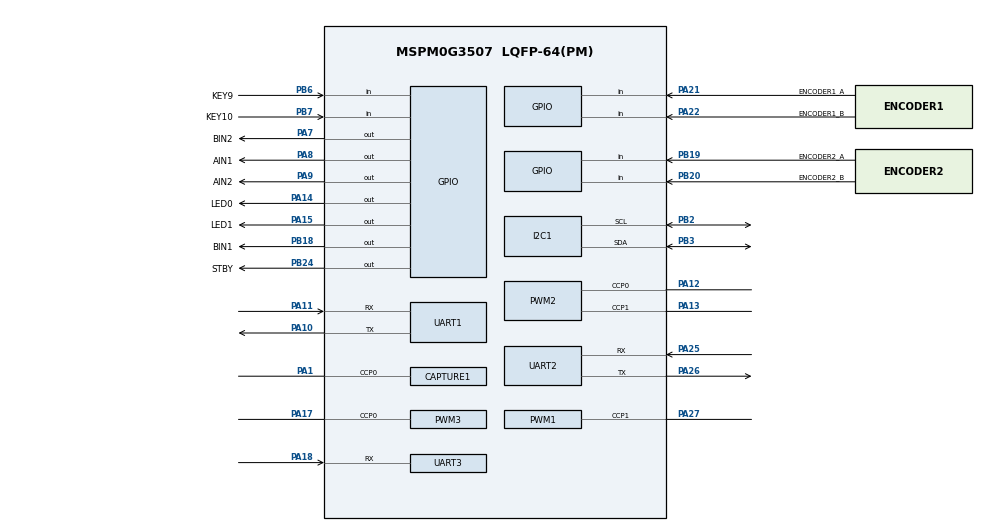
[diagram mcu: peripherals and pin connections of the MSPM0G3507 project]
/**
 * These arguments were used when this file was generated. They will be automatically applied on subsequent loads
 * via the GUI or CLI. Run CLI with '--help' for additional information on how to override these arguments.
 * @cliArgs --device "MSPM0G350X" --part "Default" --package "LQFP-64(PM)" --product "mspm0_sdk@2.10.00.04"
 * @v2CliArgs --device "MSPM0G3507" --package "LQFP-64(PM)" --product "mspm0_sdk@2.10.00.04"
 * @versions {"tool":"1.26.2+4477"}
 */

/**
 * Import the modules used in this configuration.
 */
const ADC12    = scripting.addModule("/ti/driverlib/ADC12", {}, false);
const ADC121   = ADC12.addInstance();
const CAPTURE  = scripting.addModule("/ti/driverlib/CAPTURE", {}, false);
const CAPTURE1 = CAPTURE.addInstance();
const GPIO     = scripting.addModule("/ti/driverlib/GPIO", {}, false);
const GPIO1    = GPIO.addInstance();
const GPIO2    = GPIO.addInstance();
const GPIO3    = GPIO.addInstance();
const I2C      = scripting.addModule("/ti/driverlib/I2C", {}, false);
const I2C1     = I2C.addInstance();
const PWM      = scripting.addModule("/ti/driverlib/PWM", {}, false);
const PWM1     = PWM.addInstance();
const PWM2     = PWM.addInstance();
const PWM3     = PWM.addInstance();
const SYSCTL   = scripting.addModule("/ti/driverlib/SYSCTL");
const SYSTICK  = scripting.addModule("/ti/driverlib/SYSTICK");
const TIMER    = scripting.addModule("/ti/driverlib/TIMER", {}, false);
const TIMER1   = TIMER.addInstance();
const UART     = scripting.addModule("/ti/driverlib/UART", {}, false);
const UART1    = UART.addInstance();
const UART2    = UART.addInstance();
const UART3    = UART.addInstance();
const VREF     = scripting.addModule("/ti/driverlib/VREF");

/**
 * Write custom configuration values to the imported modules.
 */
const divider9       = system.clockTree["UDIV"];
divider9.divideValue = 2;

const multiplier2         = system.clockTree["PLL_QDIV"];
multiplier2.multiplyValue = 5;

const mux4       = system.clockTree["EXHFMUX"];
mux4.inputSelect = "EXHFMUX_XTAL";

const mux8       = system.clockTree["HSCLKMUX"];
mux8.inputSelect = "HSCLKMUX_SYSPLL0";

const pinFunction4     = system.clockTree["HFXT"];
pinFunction4.inputFreq = 40;
pinFunction4.enable    = true;

ADC121.$name                      = "xuanniu";
ADC121.adcMem0vref                = "VREF";
ADC121.adcMem0chansel             = "DL_ADC12_INPUT_CHAN_1";
ADC121.repeatMode                 = true;
ADC121.peripheral.adcPin1.$assign = "PA16";
ADC121.adcPin1Config.$name        = "ti_driverlib_gpio_GPIOPinGeneric4";

const Board = scripting.addModule("/ti/driverlib/Board", {}, false);

CAPTURE1.$name                              = "CAPTURE_ULTRASONIC";
CAPTURE1.timerClkPrescale                   = 80;
CAPTURE1.timerPeriod                        = "50 ms";
CAPTURE1.captMode                           = "PULSE_WIDTH_UP";
CAPTURE1.peripheral.ccp0Pin.$assign         = "PA1";
CAPTURE1.ccp0PinConfig.hideOutputInversion  = scripting.forceWrite(false);
CAPTURE1.ccp0PinConfig.onlyInternalResistor = scripting.forceWrite(false);
CAPTURE1.ccp0PinConfig.passedPeripheralType = scripting.forceWrite("Digital");
CAPTURE1.ccp0PinConfig.$name                = "ti_driverlib_gpio_GPIOPinGeneric10";

GPIO1.$name                         = "LED";
GPIO1.associatedPins.create(2);
GPIO1.associatedPins[0].$name       = "LED0";
GPIO1.associatedPins[0].pin.$assign = "PA14";
GPIO1.associatedPins[1].$name       = "LED1";
GPIO1.associatedPins[1].pin.$assign = "PA15";

GPIO2.$name                              = "KEY";
GPIO2.associatedPins.create(2);
GPIO2.associatedPins[0].$name            = "KEY9";
GPIO2.associatedPins[0].direction        = "INPUT";
GPIO2.associatedPins[0].internalResistor = "PULL_DOWN";
GPIO2.associatedPins[0].interruptEn      = true;
GPIO2.associatedPins[0].polarity         = "RISE";
GPIO2.associatedPins[0].pin.$assign      = "PB6";
GPIO2.associatedPins[1].$name            = "KEY10";
GPIO2.associatedPins[1].direction        = "INPUT";
GPIO2.associatedPins[1].internalResistor = "PULL_DOWN";
GPIO2.associatedPins[1].interruptEn      = true;
GPIO2.associatedPins[1].polarity         = "RISE";
GPIO2.associatedPins[1].pin.$assign      = "PB7";

GPIO3.$name                              = "DC_MOTOR";
GPIO3.associatedPins.create(9);
GPIO3.associatedPins[0].$name            = "AIN1";
GPIO3.associatedPins[0].pin.$assign      = "PA8";
GPIO3.associatedPins[1].$name            = "AIN2";
GPIO3.associatedPins[1].pin.$assign      = "PA9";
GPIO3.associatedPins[2].$name            = "STBY";
GPIO3.associatedPins[2].pin.$assign      = "PB24";
GPIO3.associatedPins[3].$name            = "BIN1";
GPIO3.associatedPins[3].pin.$assign      = "PB18";
GPIO3.associatedPins[4].$name            = "BIN2";
GPIO3.associatedPins[4].pin.$assign      = "PA7";
GPIO3.associatedPins[5].$name            = "ENCODER1_A";
GPIO3.associatedPins[5].direction        = "INPUT";
GPIO3.associatedPins[5].interruptEn      = true;
GPIO3.associatedPins[5].polarity         = "RISE";
GPIO3.associatedPins[5].internalResistor = "PULL_DOWN";
GPIO3.associatedPins[5].pin.$assign      = "PA21";
GPIO3.associatedPins[6].$name            = "ENCODER1_B";
GPIO3.associatedPins[6].direction        = "INPUT";
GPIO3.associatedPins[6].internalResistor = "PULL_DOWN";
GPIO3.associatedPins[6].pin.$assign      = "PA22";
GPIO3.associatedPins[7].$name            = "ENCODER2_A";
GPIO3.associatedPins[7].direction        = "INPUT";
GPIO3.associatedPins[7].internalResistor = "PULL_DOWN";
GPIO3.associatedPins[7].interruptEn      = true;
GPIO3.associatedPins[7].polarity         = "RISE";
GPIO3.associatedPins[7].pin.$assign      = "PB19";
GPIO3.associatedPins[8].$name            = "ENCODER2_B";
GPIO3.associatedPins[8].direction        = "INPUT";
GPIO3.associatedPins[8].internalResistor = "PULL_DOWN";
GPIO3.associatedPins[8].pin.$assign      = "PB20";

I2C1.$name                             = "OLED";
I2C1.basicEnableController             = true;
I2C1.advDigitalGlitchFilter            = "CLOCKS_1";
I2C1.advControllerRXFIFOTRIG           = "BYTES_8";
I2C1.advControllerTXFIFOTRIG           = "BYTES_7";
I2C1.enableDMAEvent1                   = false;
I2C1.enableDMAEvent2                   = false;
I2C1.basicControllerStandardBusSpeed   = "Fast";
I2C1.peripheral.$assign                = "I2C1";
I2C1.peripheral.sdaPin.$assign         = "PB3";
I2C1.peripheral.sclPin.$assign         = "PB2";
I2C1.sdaPinConfig.hideOutputInversion  = scripting.forceWrite(false);
I2C1.sdaPinConfig.onlyInternalResistor = scripting.forceWrite(false);
I2C1.sdaPinConfig.passedPeripheralType = scripting.forceWrite("Digital");
I2C1.sdaPinConfig.$name                = "ti_driverlib_gpio_GPIOPinGeneric0";
I2C1.sdaPinConfig.enableConfig         = true;
I2C1.sdaPinConfig.internalResistor     = "PULL_UP";
I2C1.sclPinConfig.hideOutputInversion  = scripting.forceWrite(false);
I2C1.sclPinConfig.onlyInternalResistor = scripting.forceWrite(false);
I2C1.sclPinConfig.passedPeripheralType = scripting.forceWrite("Digital");
I2C1.sclPinConfig.$name                = "ti_driverlib_gpio_GPIOPinGeneric1";
I2C1.sclPinConfig.enableConfig         = true;
I2C1.sclPinConfig.internalResistor     = "PULL_UP";

PWM1.$name                              = "SERVO";
PWM1.clockDivider                       = 8;
PWM1.clockPrescale                      = 100;
PWM1.pwmMode                            = "EDGE_ALIGN_UP";
PWM1.ccIndex                            = [1];
PWM1.timerCount                         = 2000;
PWM1.timerStartTimer                    = true;
PWM1.ccp1PinConfig.direction            = scripting.forceWrite("OUTPUT");
PWM1.ccp1PinConfig.hideOutputInversion  = scripting.forceWrite(false);
PWM1.ccp1PinConfig.onlyInternalResistor = scripting.forceWrite(false);
PWM1.ccp1PinConfig.passedPeripheralType = scripting.forceWrite("Digital");
PWM1.ccp1PinConfig.$name                = "ti_driverlib_gpio_GPIOPinGeneric7";
PWM1.peripheral.$assign                 = "TIMG7";
PWM1.peripheral.ccp1Pin.$assign         = "PA27";
PWM1.PWM_CHANNEL_1.$name                = "ti_driverlib_pwm_PWMTimerCC0";
PWM1.PWM_CHANNEL_1.dutyCycle            = 7.5;

PWM2.timerStartTimer                    = true;
PWM2.$name                              = "PWM_MOTOR";
PWM2.timerCount                         = 4000;
PWM2.pwmMode                            = "EDGE_ALIGN_UP";
PWM2.peripheral.$assign                 = "TIMG0";
PWM2.peripheral.ccp0Pin.$assign         = "PA12";
PWM2.peripheral.ccp1Pin.$assign         = "PA13";
PWM2.PWM_CHANNEL_0.$name                = "ti_driverlib_pwm_PWMTimerCC1";
PWM2.PWM_CHANNEL_1.$name                = "ti_driverlib_pwm_PWMTimerCC2";
PWM2.ccp0PinConfig.$name                = "ti_driverlib_gpio_GPIOPinGeneric6";
PWM2.ccp0PinConfig.direction            = scripting.forceWrite("OUTPUT");
PWM2.ccp0PinConfig.hideOutputInversion  = scripting.forceWrite(false);
PWM2.ccp0PinConfig.onlyInternalResistor = scripting.forceWrite(false);
PWM2.ccp0PinConfig.passedPeripheralType = scripting.forceWrite("Digital");
PWM2.ccp1PinConfig.direction            = scripting.forceWrite("OUTPUT");
PWM2.ccp1PinConfig.hideOutputInversion  = scripting.forceWrite(false);
PWM2.ccp1PinConfig.onlyInternalResistor = scripting.forceWrite(false);
PWM2.ccp1PinConfig.passedPeripheralType = scripting.forceWrite("Digital");
PWM2.ccp1PinConfig.$name                = "ti_driverlib_gpio_GPIOPinGeneric8";

PWM3.$name                              = "PWM_ULTRASONIC";
PWM3.clockPrescale                      = 250;
PWM3.timerStartTimer                    = true;
PWM3.ccIndex                            = [0];
PWM3.timerCount                         = 64000;
PWM3.PWM_CHANNEL_0.$name                = "ti_driverlib_pwm_PWMTimerCC3";
PWM3.PWM_CHANNEL_0.dutyCycle            = 50;
PWM3.ccp0PinConfig.direction            = scripting.forceWrite("OUTPUT");
PWM3.ccp0PinConfig.hideOutputInversion  = scripting.forceWrite(false);
PWM3.ccp0PinConfig.onlyInternalResistor = scripting.forceWrite(false);
PWM3.ccp0PinConfig.passedPeripheralType = scripting.forceWrite("Digital");
PWM3.ccp0PinConfig.$name                = "ti_driverlib_gpio_GPIOPinGeneric9";
PWM3.peripheral.ccp0Pin.$assign         = "PA17";

SYSCTL.forceDefaultClkConfig = true;
SYSCTL.clockTreeEn           = true;

SYSTICK.periodEnable      = true;
SYSTICK.interruptEnable   = true;
SYSTICK.interruptPriority = "0";
SYSTICK.period            = 80000;
SYSTICK.systickEnable     = true;

TIMER1.$name              = "MOTOR_PID";
TIMER1.timerMode          = "PERIODIC_UP";
TIMER1.timerClkPrescale   = 100;
TIMER1.timerPeriod        = "50ms";
TIMER1.interrupts         = ["LOAD"];
TIMER1.peripheral.$assign = "TIMA0";

UART1.$name                            = "DEBUG";
UART1.targetBaudRate                   = 115200;
UART1.enableFIFO                       = true;
UART1.txFifoThreshold                  = "DL_UART_TX_FIFO_LEVEL_1_4_EMPTY";
UART1.rxTimeoutValue                   = 10;
UART1.enabledInterrupts                = ["RX","RX_TIMEOUT_ERROR"];
UART1.peripheral.$assign               = "UART0";
UART1.peripheral.rxPin.$assign         = "PA11";
UART1.peripheral.txPin.$assign         = "PA10";
UART1.txPinConfig.direction            = scripting.forceWrite("OUTPUT");
UART1.txPinConfig.hideOutputInversion  = scripting.forceWrite(false);
UART1.txPinConfig.onlyInternalResistor = scripting.forceWrite(false);
UART1.txPinConfig.passedPeripheralType = scripting.forceWrite("Digital");
UART1.txPinConfig.$name                = "ti_driverlib_gpio_GPIOPinGeneric2";
UART1.rxPinConfig.hideOutputInversion  = scripting.forceWrite(false);
UART1.rxPinConfig.onlyInternalResistor = scripting.forceWrite(false);
UART1.rxPinConfig.passedPeripheralType = scripting.forceWrite("Digital");
UART1.rxPinConfig.$name                = "ti_driverlib_gpio_GPIOPinGeneric3";

UART2.$name                            = "PRINT";
UART2.targetBaudRate                   = 115200;
UART2.enableFIFO                       = true;
UART2.txFifoThreshold                  = "DL_UART_TX_FIFO_LEVEL_1_4_EMPTY";
UART2.rxTimeoutValue                   = 10;
UART2.enabledInterrupts                = ["RX","RX_TIMEOUT_ERROR"];
UART2.uartClkDiv                       = "2";
UART2.rxFifoThreshold                  = "DL_UART_RX_FIFO_LEVEL_FULL";
UART2.peripheral.$assign               = "UART3";
UART2.peripheral.rxPin.$assign         = "PA25";
UART2.peripheral.txPin.$assign         = "PA26";
UART2.txPinConfig.direction            = scripting.forceWrite("OUTPUT");
UART2.txPinConfig.hideOutputInversion  = scripting.forceWrite(false);
UART2.txPinConfig.onlyInternalResistor = scripting.forceWrite(false);
UART2.txPinConfig.passedPeripheralType = scripting.forceWrite("Digital");
UART2.txPinConfig.$name                = "ti_driverlib_gpio_GPIOPinGeneric11";
UART2.rxPinConfig.hideOutputInversion  = scripting.forceWrite(false);
UART2.rxPinConfig.onlyInternalResistor = scripting.forceWrite(false);
UART2.rxPinConfig.passedPeripheralType = scripting.forceWrite("Digital");
UART2.rxPinConfig.$name                = "ti_driverlib_gpio_GPIOPinGeneric12";

UART3.$name                            = "UART_WIT";
UART3.targetBaudRate                   = 115200;
UART3.direction                        = "RX";
UART3.enableFIFO                       = true;
UART3.rxTimeoutValue                   = 1;
UART3.enabledInterrupts                = ["RX_TIMEOUT_ERROR"];
UART3.enabledDMARXTriggers             = "DL_UART_DMA_INTERRUPT_RX";
UART3.rxPinConfig.$name                = "ti_driverlib_gpio_GPIOPinGeneric14";
UART3.rxPinConfig.hideOutputInversion  = scripting.forceWrite(false);
UART3.rxPinConfig.onlyInternalResistor = scripting.forceWrite(false);
UART3.rxPinConfig.passedPeripheralType = scripting.forceWrite("Digital");
UART3.peripheral.rxPin.$assign         = "PA18";
UART3.DMA_CHANNEL_RX.$name             = "DMA_WIT";
UART3.DMA_CHANNEL_RX.addressMode       = "f2b";
UART3.DMA_CHANNEL_RX.srcLength         = "BYTE";
UART3.DMA_CHANNEL_RX.dstLength         = "BYTE";

VREF.basicIntVolt           = "DL_VREF_BUFCONFIG_OUTPUT_2_5V";
VREF.profile                = "INT_2_5_V";
VREF.vrefPosPinConfig.$name = "ti_driverlib_gpio_GPIOPinGeneric5";

/**
 * Pinmux solution for unlocked pins/peripherals. This ensures that minor changes to the automatic solver in a future
 * version of the tool will not impact the pinmux you originally saw.  These lines can be completely deleted in order to
 * re-solve from scratch.
 */
pinFunction4.peripheral.$suggestSolution           = "SYSCTL";
pinFunction4.peripheral.hfxInPin.$suggestSolution  = "PA5";
pinFunction4.peripheral.hfxOutPin.$suggestSolution = "PA6";
ADC121.peripheral.$suggestSolution                 = "ADC1";
Board.peripheral.$suggestSolution                  = "DEBUGSS";
Board.peripheral.swclkPin.$suggestSolution         = "PA20";
Board.peripheral.swdioPin.$suggestSolution         = "PA19";
CAPTURE1.peripheral.$suggestSolution               = "TIMG8";
PWM3.peripheral.$suggestSolution                   = "TIMA1";
UART3.peripheral.$suggestSolution                  = "UART1";
UART3.DMA_CHANNEL_RX.peripheral.$suggestSolution   = "DMA_CH0";
VREF.peripheral.$suggestSolution                   = "VREF";
VREF.peripheral.vrefPosPin.$suggestSolution        = "PA23";
